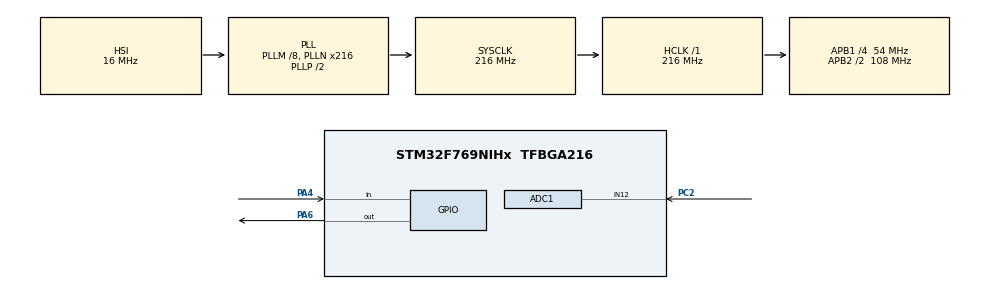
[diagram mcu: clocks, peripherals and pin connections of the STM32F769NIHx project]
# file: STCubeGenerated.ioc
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ADC1.Channel-0\#ChannelRegularConversion=ADC_CHANNEL_12
ADC1.NbrOfConversionFlag=1
ADC1.Rank-0\#ChannelRegularConversion=1
ADC1.SamplingTime-0\#ChannelRegularConversion=ADC_SAMPLETIME_3CYCLES
ADC1.master=1
Mcu.Family=STM32F7
Mcu.Name=STM32F769NIHx
Mcu.Package=TFBGA216
NVIC.PriorityGroup=NVIC_PRIORITYGROUP_4
PA4.GPIO_PuPd=GPIO_PULLDOWN
PA4.Signal=GPIO_Input
PA6.Signal=GPIO_Output
PC2.Signal=ADCx_IN12
ProjectManager.HeapSize=0x200
ProjectManager.StackSize=0x400
ProjectManager.TargetToolchain=MDK-ARM V5
RCC.AHBFreq_Value=216000000
RCC.APB1CLKDivider=RCC_HCLK_DIV4
RCC.APB1Freq_Value=54000000
RCC.APB1TimFreq_Value=108000000
RCC.APB2CLKDivider=RCC_HCLK_DIV2
RCC.APB2Freq_Value=108000000
RCC.APB2TimFreq_Value=216000000
RCC.CortexFreq_Value=216000000
RCC.HCLKFreq_Value=216000000
RCC.HSE_VALUE=25000000
RCC.HSI_VALUE=16000000
RCC.LSE_VALUE=32768
RCC.PLLM=8
RCC.PLLN=216
RCC.SYSCLKFreq_VALUE=216000000
RCC.SYSCLKSource=RCC_SYSCLKSOURCE_PLLCLK
RCC.USBFreq_Value=216000000
RCC.VCOOutputFreq_Value=432000000
SH.ADCx_IN12.0=ADC1_IN12,IN12
board=custom

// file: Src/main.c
/**
  ******************************************************************************
  * @file           : main.c
  * @brief          : Main program body
  ******************************************************************************
  ** This notice applies to any and all portions of this file
  * that are not between comment pairs USER CODE BEGIN and
  * USER CODE END. Other portions of this file, whether
  * inserted by the user or by software development tools
  * are owned by their respective copyright owners.
  *
  * COPYRIGHT(c) 2018 STMicroelectronics
  *
  * Redistribution and use in source and binary forms, with or without modification,
  * are permitted provided that the following conditions are met:
  *   1. Redistributions of source code must retain the above copyright notice,
  *      this list of conditions and the following disclaimer.
  *   2. Redistributions in binary form must reproduce the above copyright notice,
  *      this list of conditions and the following disclaimer in the documentation
  *      and/or other materials provided with the distribution.
  *   3. Neither the name of STMicroelectronics nor the names of its contributors
  *      may be used to endorse or promote products derived from this software
  *      without specific prior written permission.
  *
  * THIS SOFTWARE IS PROVIDED BY THE COPYRIGHT HOLDERS AND CONTRIBUTORS "AS IS"
  * AND ANY EXPRESS OR IMPLIED WARRANTIES, INCLUDING, BUT NOT LIMITED TO, THE
  * IMPLIED WARRANTIES OF MERCHANTABILITY AND FITNESS FOR A PARTICULAR PURPOSE ARE
  * DISCLAIMED. IN NO EVENT SHALL THE COPYRIGHT HOLDER OR CONTRIBUTORS BE LIABLE
  * FOR ANY DIRECT, INDIRECT, INCIDENTAL, SPECIAL, EXEMPLARY, OR CONSEQUENTIAL
  * DAMAGES (INCLUDING, BUT NOT LIMITED TO, PROCUREMENT OF SUBSTITUTE GOODS OR
  * SERVICES; LOSS OF USE, DATA, OR PROFITS; OR BUSINESS INTERRUPTION) HOWEVER
  * CAUSED AND ON ANY THEORY OF LIABILITY, WHETHER IN CONTRACT, STRICT LIABILITY,
  * OR TORT (INCLUDING NEGLIGENCE OR OTHERWISE) ARISING IN ANY WAY OUT OF THE USE
  * OF THIS SOFTWARE, EVEN IF ADVISED OF THE POSSIBILITY OF SUCH DAMAGE.
  *
  ******************************************************************************
  */
#include "main.h"
#include "stm32f7xx_hal.h"

/* USER CODE BEGIN Includes */
#include <stdlib.h>
#include "registers.h"

#define LED1_PORT GPIOA
#define LED1_PIN GPIO_PIN_6 // Discovery Board A0
#define LED2_PORT GPIOA
#define LED2_PIN GPIO_PIN_4 // Discovery Board A1
#define LED3_PORT GPIOA
#define LED3_PIN GPIO_PIN_11 // Discovery Board D10
#define LED4_PORT GPIOC
#define LED4_PIN GPIO_PIN_6 // Discovery Board D1

/* USER CODE END Includes */

ADC_HandleTypeDef hadc1;

/* USER CODE BEGIN PV */
/* Private variables ---------------------------------------------------------*/
uint16_t adcValue = 1000;
shiftRegister mainRegister;
int sampleCount = 0;
int sampleFlag = 0;
/* USER CODE END PV */

void SystemClock_Config(void);
static void MX_GPIO_Init(void);
static void MX_ADC1_Init(void);

/* USER CODE BEGIN PFP */
/* Private function prototypes -----------------------------------------------*/
void controlLEDBrightness(void);
/* USER CODE END PFP */

int main(void)
{

  /* MCU Configuration----------------------------------------------------------*/

  /* Reset of all peripherals, Initializes the Flash interface and the Systick. */
  HAL_Init();

  /* Configure the system clock */
  SystemClock_Config();

  /* Initialize all configured peripherals */
  MX_GPIO_Init();
  MX_ADC1_Init();
  /* USER CODE BEGIN 2 */
	HAL_ADC_Start(&hadc1);
	initRegister(&mainRegister,4,160);
	updateTapHolds(&mainRegister);
	updateTapLocs(&mainRegister);
	updateTapVals(&mainRegister);
	HAL_Delay(1000);
  /* USER CODE END 2 */

  /* Infinite loop */
  /* USER CODE BEGIN WHILE */
  while (1)
  {

		if (HAL_ADC_PollForConversion(&hadc1,5) == HAL_OK) {
			adcValue = 2*HAL_ADC_GetValue(&hadc1);
		}

		if (sampleFlag == 1) {
			HAL_Delay(1);
			if (sampleCount == mainRegister.feedOutID+1) mainRegister.feedMix = 1;
			sampleValue(&mainRegister,adcValue);
			updateTapHolds(&mainRegister);
			updateTapLocs(&mainRegister);
			updateTapVals(&mainRegister);
			sampleCount++;
			sampleFlag = 0;
		}

		controlLEDBrightness();

  /* USER CODE END WHILE */

  }

}

void SystemClock_Config(void)
{

  RCC_OscInitTypeDef RCC_OscInitStruct;
  RCC_ClkInitTypeDef RCC_ClkInitStruct;

    /**Configure the main internal regulator output voltage
    */
  __HAL_RCC_PWR_CLK_ENABLE();

  __HAL_PWR_VOLTAGESCALING_CONFIG(PWR_REGULATOR_VOLTAGE_SCALE1);

    /**Initializes the CPU, AHB and APB busses clocks
    */
  RCC_OscInitStruct.OscillatorType = RCC_OSCILLATORTYPE_HSI;
  RCC_OscInitStruct.HSIState = RCC_HSI_ON;
  RCC_OscInitStruct.HSICalibrationValue = 16;
  RCC_OscInitStruct.PLL.PLLState = RCC_PLL_ON;
  RCC_OscInitStruct.PLL.PLLSource = RCC_PLLSOURCE_HSI;
  RCC_OscInitStruct.PLL.PLLM = 8;
  RCC_OscInitStruct.PLL.PLLN = 216;
  RCC_OscInitStruct.PLL.PLLP = RCC_PLLP_DIV2;
  RCC_OscInitStruct.PLL.PLLQ = 2;
  if (HAL_RCC_OscConfig(&RCC_OscInitStruct) != HAL_OK)
  {
    _Error_Handler(__FILE__, __LINE__);
  }

    /**Activate the Over-Drive mode
    */
  if (HAL_PWREx_EnableOverDrive() != HAL_OK)
  {
    _Error_Handler(__FILE__, __LINE__);
  }

    /**Initializes the CPU, AHB and APB busses clocks
    */
  RCC_ClkInitStruct.ClockType = RCC_CLOCKTYPE_HCLK|RCC_CLOCKTYPE_SYSCLK
                              |RCC_CLOCKTYPE_PCLK1|RCC_CLOCKTYPE_PCLK2;
  RCC_ClkInitStruct.SYSCLKSource = RCC_SYSCLKSOURCE_PLLCLK;
  RCC_ClkInitStruct.AHBCLKDivider = RCC_SYSCLK_DIV1;
  RCC_ClkInitStruct.APB1CLKDivider = RCC_HCLK_DIV4;
  RCC_ClkInitStruct.APB2CLKDivider = RCC_HCLK_DIV2;

  if (HAL_RCC_ClockConfig(&RCC_ClkInitStruct, FLASH_LATENCY_7) != HAL_OK)
  {
    _Error_Handler(__FILE__, __LINE__);
  }

    /**Configure the Systick interrupt time
    */
  HAL_SYSTICK_Config(HAL_RCC_GetHCLKFreq()/1000);

    /**Configure the Systick
    */
  HAL_SYSTICK_CLKSourceConfig(SYSTICK_CLKSOURCE_HCLK);

  /* SysTick_IRQn interrupt configuration */
  HAL_NVIC_SetPriority(SysTick_IRQn, 0, 0);
}

/* ADC1 init function */
static void MX_ADC1_Init(void)
{

  ADC_ChannelConfTypeDef sConfig;

    /**Configure the global features of the ADC (Clock, Resolution, Data Alignment and number of conversion)
    */
  hadc1.Instance = ADC1;
  hadc1.Init.ClockPrescaler = ADC_CLOCK_SYNC_PCLK_DIV4;
  hadc1.Init.Resolution = ADC_RESOLUTION_12B;
  hadc1.Init.ScanConvMode = ADC_SCAN_DISABLE;
  hadc1.Init.ContinuousConvMode = ENABLE;
  hadc1.Init.DiscontinuousConvMode = DISABLE;
  hadc1.Init.ExternalTrigConvEdge = ADC_EXTERNALTRIGCONVEDGE_NONE;
  hadc1.Init.ExternalTrigConv = ADC_SOFTWARE_START;
  hadc1.Init.DataAlign = ADC_DATAALIGN_RIGHT;
  hadc1.Init.NbrOfConversion = 1;
  hadc1.Init.DMAContinuousRequests = DISABLE;
  hadc1.Init.EOCSelection = DISABLE;
  if (HAL_ADC_Init(&hadc1) != HAL_OK)
  {
    _Error_Handler(__FILE__, __LINE__);
  }

    /**Configure for the selected ADC regular channel its corresponding rank in the sequencer and its sample time.
    */
  sConfig.Channel = ADC_CHANNEL_12;
  sConfig.Rank = ADC_REGULAR_RANK_1;
  sConfig.SamplingTime = ADC_SAMPLETIME_3CYCLES;
  if (HAL_ADC_ConfigChannel(&hadc1, &sConfig) != HAL_OK)
  {
    _Error_Handler(__FILE__, __LINE__);
  }

}

/** Configure pins as
        * Analog
        * Input
        * Output
        * EVENT_OUT
        * EXTI
*/
static void MX_GPIO_Init(void)
{

  GPIO_InitTypeDef GPIO_InitStruct;

  /* GPIO Ports Clock Enable */
  __HAL_RCC_GPIOC_CLK_ENABLE();
  __HAL_RCC_GPIOA_CLK_ENABLE();

  /*Configure GPIO pin Output Level */
  HAL_GPIO_WritePin(LED1_PORT, LED1_PIN, GPIO_PIN_RESET);
	HAL_GPIO_WritePin(LED2_PORT, LED2_PIN, GPIO_PIN_RESET);
	HAL_GPIO_WritePin(LED3_PORT, LED3_PIN, GPIO_PIN_RESET);
	HAL_GPIO_WritePin(LED4_PORT, LED4_PIN, GPIO_PIN_RESET);
  HAL_GPIO_WritePin(GPIOA, GPIO_PIN_12, GPIO_PIN_SET);  // make sure potentiometer has voltage reference

	/*Configure GPIO pin : LED1 */ // A0 on discovery, toggles LED
  GPIO_InitStruct.Pin = LED1_PIN;
  GPIO_InitStruct.Mode = GPIO_MODE_OUTPUT_PP;
  GPIO_InitStruct.Pull = GPIO_NOPULL;
  GPIO_InitStruct.Speed = GPIO_SPEED_FREQ_LOW;
  HAL_GPIO_Init(LED1_PORT, &GPIO_InitStruct);

  /*Configure GPIO pin : LED2*/ // Unused
  GPIO_InitStruct.Pin = LED2_PIN;
  GPIO_InitStruct.Mode = GPIO_MODE_OUTPUT_PP;
  GPIO_InitStruct.Pull = GPIO_NOPULL;
  GPIO_InitStruct.Speed = GPIO_SPEED_FREQ_LOW;
  HAL_GPIO_Init(LED2_PORT, &GPIO_InitStruct);

	/*Configure GPIO pin : LED3 */ // Unused
  GPIO_InitStruct.Pin = LED3_PIN;
  GPIO_InitStruct.Mode = GPIO_MODE_OUTPUT_PP;
  GPIO_InitStruct.Pull = GPIO_NOPULL;
  GPIO_InitStruct.Speed = GPIO_SPEED_FREQ_LOW;
  HAL_GPIO_Init(LED3_PORT, &GPIO_InitStruct);

	/*Configure GPIO pin : LED4 */ // Unused
  GPIO_InitStruct.Pin = LED4_PIN;
  GPIO_InitStruct.Mode = GPIO_MODE_OUTPUT_PP;
  GPIO_InitStruct.Pull = GPIO_NOPULL;
  GPIO_InitStruct.Speed = GPIO_SPEED_FREQ_LOW;
  HAL_GPIO_Init(LED4_PORT, &GPIO_InitStruct);;

	/*Configure GPIO pin : PA12 */ // D13 on discovery, provides power to potentiometer
  GPIO_InitStruct.Pin = GPIO_PIN_12;
  GPIO_InitStruct.Mode = GPIO_MODE_OUTPUT_PP;
  GPIO_InitStruct.Pull = GPIO_NOPULL;
  GPIO_InitStruct.Speed = GPIO_SPEED_FREQ_LOW;
  HAL_GPIO_Init(GPIOA, &GPIO_InitStruct);

}

/* USER CODE BEGIN 4 */
void controlLEDBrightness(void) {
	HAL_GPIO_WritePin(LED1_PORT,LED1_PIN,GPIO_PIN_SET);
	HAL_GPIO_WritePin(LED2_PORT,LED2_PIN,GPIO_PIN_SET);
	HAL_GPIO_WritePin(LED3_PORT,LED3_PIN,GPIO_PIN_SET);
	HAL_GPIO_WritePin(LED4_PORT,LED4_PIN,GPIO_PIN_SET);
	for (int i = 0; i<8192; i++) {
		if (i > mainRegister.taps[0].val) {
			HAL_GPIO_WritePin(LED1_PORT,LED1_PIN,GPIO_PIN_RESET);
		}
		if (i > mainRegister.taps[1].val) {
			HAL_GPIO_WritePin(LED2_PORT,LED2_PIN,GPIO_PIN_RESET);
		}
		if (i > mainRegister.taps[2].val ) {
			HAL_GPIO_WritePin(LED3_PORT,LED3_PIN,GPIO_PIN_RESET);
		}
		if (i > mainRegister.taps[3].val) {
			HAL_GPIO_WritePin(LED4_PORT,LED4_PIN,GPIO_PIN_RESET);
		}
	}
}
/* USER CODE END 4 */

void _Error_Handler(char *file, int line)
{
  while(1)
  {
  }
}

/************************ (C) COPYRIGHT STMicroelectronics *****END OF FILE****/
